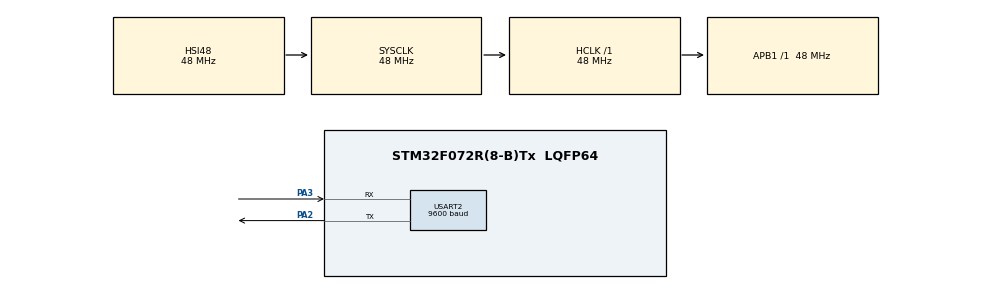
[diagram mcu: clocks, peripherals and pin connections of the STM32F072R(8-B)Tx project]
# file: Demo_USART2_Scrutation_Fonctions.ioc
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Mcu.Family=STM32F0
Mcu.Name=STM32F072R(8-B)Tx
Mcu.Package=LQFP64
PA2.Mode=Asynchronous
PA2.Signal=USART2_TX
PA3.Mode=Asynchronous
PA3.Signal=USART2_RX
ProjectManager.HeapSize=0x200
ProjectManager.StackSize=0x400
ProjectManager.TargetToolchain=TrueSTUDIO
RCC.AHBFreq_Value=48000000
RCC.APB1Freq_Value=48000000
RCC.APB1TimFreq_Value=48000000
RCC.HCLKFreq_Value=48000000
RCC.SYSCLKFreq_VALUE=48000000
RCC.SYSCLKSource=RCC_SYSCLKSOURCE_HSI48
USART2.BaudRate=9600
USART2.VirtualMode-Asynchronous=VM_ASYNC
USART2.WordLength=WORDLENGTH_8B
board=Demo_USART2_Scrutation_Fonctions

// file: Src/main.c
/**
  ******************************************************************************
  * File Name          : main.c
  * Description        : Main program body
  ******************************************************************************
  ** This notice applies to any and all portions of this file
  * that are not between comment pairs USER CODE BEGIN and
  * USER CODE END. Other portions of this file, whether
  * inserted by the user or by software development tools
  * are owned by their respective copyright owners.
  *
  * COPYRIGHT(c) 2020 STMicroelectronics
  *
  * Redistribution and use in source and binary forms, with or without modification,
  * are permitted provided that the following conditions are met:
  *   1. Redistributions of source code must retain the above copyright notice,
  *      this list of conditions and the following disclaimer.
  *   2. Redistributions in binary form must reproduce the above copyright notice,
  *      this list of conditions and the following disclaimer in the documentation
  *      and/or other materials provided with the distribution.
  *   3. Neither the name of STMicroelectronics nor the names of its contributors
  *      may be used to endorse or promote products derived from this software
  *      without specific prior written permission.
  *
  * THIS SOFTWARE IS PROVIDED BY THE COPYRIGHT HOLDERS AND CONTRIBUTORS "AS IS"
  * AND ANY EXPRESS OR IMPLIED WARRANTIES, INCLUDING, BUT NOT LIMITED TO, THE
  * IMPLIED WARRANTIES OF MERCHANTABILITY AND FITNESS FOR A PARTICULAR PURPOSE ARE
  * DISCLAIMED. IN NO EVENT SHALL THE COPYRIGHT HOLDER OR CONTRIBUTORS BE LIABLE
  * FOR ANY DIRECT, INDIRECT, INCIDENTAL, SPECIAL, EXEMPLARY, OR CONSEQUENTIAL
  * DAMAGES (INCLUDING, BUT NOT LIMITED TO, PROCUREMENT OF SUBSTITUTE GOODS OR
  * SERVICES; LOSS OF USE, DATA, OR PROFITS; OR BUSINESS INTERRUPTION) HOWEVER
  * CAUSED AND ON ANY THEORY OF LIABILITY, WHETHER IN CONTRACT, STRICT LIABILITY,
  * OR TORT (INCLUDING NEGLIGENCE OR OTHERWISE) ARISING IN ANY WAY OUT OF THE USE
  * OF THIS SOFTWARE, EVEN IF ADVISED OF THE POSSIBILITY OF SUCH DAMAGE.
  *
  ******************************************************************************
  */

#include "main.h"
#include "stm32f0xx_hal.h"

UART_HandleTypeDef huart2;

/* USER CODE BEGIN PV */
/* Private variables ---------------------------------------------------------*/
unsigned char MessageAccueil [] = "Bienvenu EI-2I3";

/* USER CODE END PV */

void SystemClock_Config(void);
static void MX_GPIO_Init(void);
static void MX_USART2_UART_Init(void);

/* USER CODE BEGIN PFP */
/* Private function prototypes -----------------------------------------------*/
void EnvoieCharatere (unsigned char Caractere);
void Envoie_Message (unsigned char *charactere);
unsigned char ReceptionCharatere (void);

/* USER CODE END PFP */

int main(void)
{

  /* USER CODE BEGIN 1 */
	unsigned char CaractereRecu;

  /* USER CODE END 1 */

  /* MCU Configuration----------------------------------------------------------*/

  /* Reset of all peripherals, Initializes the Flash interface and the Systick. */
  HAL_Init();

  /* Configure the system clock */
  SystemClock_Config();

  /* Initialize all configured peripherals */
  MX_GPIO_Init();
  MX_USART2_UART_Init();

  /* USER CODE BEGIN 2 */
  Envoie_Message (MessageAccueil);
  /* USER CODE END 2 */

  /* Infinite loop */
  while (1)
  {

  /* USER CODE BEGIN 3 */
	  CaractereRecu = ReceptionCharatere ();
	  CaractereRecu++;
	  EnvoieCharatere (CaractereRecu);

  }
  /* USER CODE END 3 */

}

/** System Clock Configuration
*/
void SystemClock_Config(void)
{

  RCC_OscInitTypeDef RCC_OscInitStruct;
  RCC_ClkInitTypeDef RCC_ClkInitStruct;
  RCC_PeriphCLKInitTypeDef PeriphClkInit;

    /**Initializes the CPU, AHB and APB busses clocks
    */
  RCC_OscInitStruct.OscillatorType = RCC_OSCILLATORTYPE_HSI48;
  RCC_OscInitStruct.HSI48State = RCC_HSI48_ON;
  RCC_OscInitStruct.PLL.PLLState = RCC_PLL_NONE;
  if (HAL_RCC_OscConfig(&RCC_OscInitStruct) != HAL_OK)
  {
    _Error_Handler(__FILE__, __LINE__);
  }

    /**Initializes the CPU, AHB and APB busses clocks
    */
  RCC_ClkInitStruct.ClockType = RCC_CLOCKTYPE_HCLK|RCC_CLOCKTYPE_SYSCLK
                              |RCC_CLOCKTYPE_PCLK1;
  RCC_ClkInitStruct.SYSCLKSource = RCC_SYSCLKSOURCE_HSI48;
  RCC_ClkInitStruct.AHBCLKDivider = RCC_SYSCLK_DIV1;
  RCC_ClkInitStruct.APB1CLKDivider = RCC_HCLK_DIV1;

  if (HAL_RCC_ClockConfig(&RCC_ClkInitStruct, FLASH_LATENCY_1) != HAL_OK)
  {
    _Error_Handler(__FILE__, __LINE__);
  }

  PeriphClkInit.PeriphClockSelection = RCC_PERIPHCLK_USART2;
  PeriphClkInit.Usart2ClockSelection = RCC_USART2CLKSOURCE_PCLK1;
  if (HAL_RCCEx_PeriphCLKConfig(&PeriphClkInit) != HAL_OK)
  {
    _Error_Handler(__FILE__, __LINE__);
  }

    /**Configure the Systick interrupt time
    */
  HAL_SYSTICK_Config(HAL_RCC_GetHCLKFreq()/1000);

    /**Configure the Systick
    */
  HAL_SYSTICK_CLKSourceConfig(SYSTICK_CLKSOURCE_HCLK);

  /* SysTick_IRQn interrupt configuration */
  HAL_NVIC_SetPriority(SysTick_IRQn, 0, 0);
}

/* USART2 init function */
static void MX_USART2_UART_Init(void)
{

  huart2.Instance = USART2;
  huart2.Init.BaudRate = 9600;
  huart2.Init.WordLength = UART_WORDLENGTH_8B;
  huart2.Init.StopBits = UART_STOPBITS_1;
  huart2.Init.Parity = UART_PARITY_NONE;
  huart2.Init.Mode = UART_MODE_TX_RX;
  huart2.Init.HwFlowCtl = UART_HWCONTROL_NONE;
  huart2.Init.OverSampling = UART_OVERSAMPLING_16;
  huart2.Init.OneBitSampling = UART_ONE_BIT_SAMPLE_DISABLE;
  huart2.AdvancedInit.AdvFeatureInit = UART_ADVFEATURE_NO_INIT;
  if (HAL_UART_Init(&huart2) != HAL_OK)
  {
    _Error_Handler(__FILE__, __LINE__);
  }

}

/** Pinout Configuration
*/
static void MX_GPIO_Init(void)
{

  /* GPIO Ports Clock Enable */
  __HAL_RCC_GPIOA_CLK_ENABLE();

}

/* USER CODE BEGIN 4 */

/*===============================================================================
  FUNCTION:     envoieCharatere(void)
  DESCRIPTION:  Envoie caractère sur la liaison série
  PARAMETERS:   Caractère
  RETURNS:      rien
  REQUIREMENTS: rien
===============================================================================*/
void EnvoieCharatere (unsigned char Caractere)
{
  USART2->TDR = Caractere;

  while (!(USART2->ISR & 1<<7))
  {
	  /* tant que le bit b7 (TXE) du registre (USART2_ISR) est a  '0' on attend ici!  */
  }
}

/*===============================================================================
  FUNCTION:     Envoie_Message(void)
  DESCRIPTION:  Envoie caractère sur la liaison série
  PARAMETERS:   pointeur Tableau de Caractères : Nom du Tableau
  RETURNS:      rien
  REQUIREMENTS: rien
===============================================================================*/
void Envoie_Message (unsigned char *charactere)
{

  while (*charactere != '\0' )
  {
    EnvoieCharatere(*charactere);
    charactere ++;
  }
  EnvoieCharatere ('\r'); // Retour chariot
}

/*----------------------------------------------------------------------------
   ReceptionCharatere
  @brief  : Recois un charactère
  @param  : rien
  @retval : Caractere recu
  effets de bords :
 *----------------------------------------------------------------------------*/
 unsigned char ReceptionCharatere (void)
 {
   unsigned char CaractereRecu=0;

   /* Attente que le registre de reception soit rempli par le code du caractere recu
  	 scrutation du bit b5 (RXNE) du registre Interrupt & status register (USARTx_ISR)
  	 si ce bit passe a '1' c'est que le caractere est recu
  	*/
  	 while (!(USART2->ISR & (1 << 5)))
  	 {
  		/* on reste dans cette boucle tant que le caracterse n'est pas arrivee
  		    tant que bit  b5 (RXNE) du registre (USART2_ISR) vaut '0'
  		*/
  	}
  	 /* Arriver ici signifie que le bit  b5 (RXNE) du registre (USART2_ISR) vaut '1' : donc on peux lire un autre caractÃ¨re */

  	/* Lecture du caractere depuis le registre UCA0RXBUF
  	   et sauvegarde du caractere recu	dans la variable Caractere_Recu
  	*/
   CaractereRecu = USART2->RDR;
    return CaractereRecu;
 }

/* USER CODE END 4 */

void _Error_Handler(char * file, int line)
{
  while(1)
  {
  }
}

/************************ (C) COPYRIGHT STMicroelectronics *****END OF FILE****/
